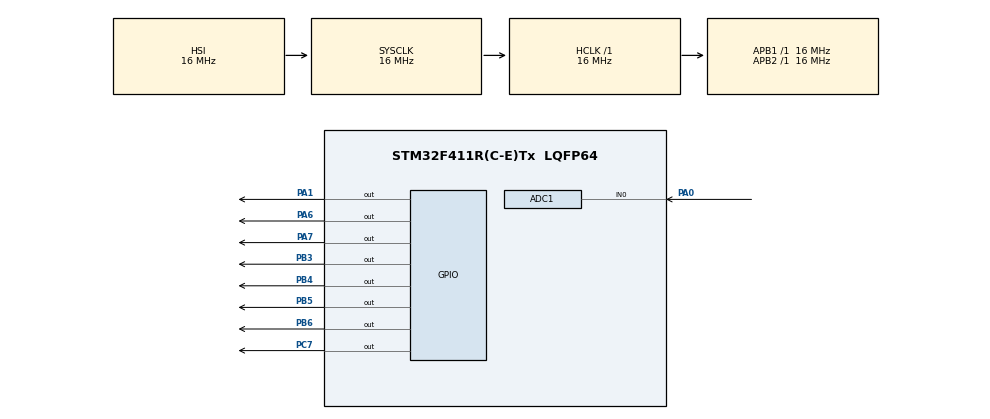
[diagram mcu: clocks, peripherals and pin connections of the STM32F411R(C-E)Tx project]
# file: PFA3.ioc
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ADC1.Channel-2\#ChannelRegularConversion=ADC_CHANNEL_0
ADC1.ClockPrescaler=ADC_CLOCK_SYNC_PCLK_DIV4
ADC1.NbrOfConversionFlag=1
ADC1.Rank-2\#ChannelRegularConversion=1
ADC1.SamplingTime-2\#ChannelRegularConversion=ADC_SAMPLETIME_3CYCLES
ADC1.master=1
Mcu.Family=STM32F4
Mcu.Name=STM32F411R(C-E)Tx
Mcu.Package=LQFP64
NVIC.PriorityGroup=NVIC_PRIORITYGROUP_4
PA0-WKUP.Signal=ADCx_IN0
PA1.Signal=GPIO_Output
PA6.Signal=GPIO_Output
PA7.Signal=GPIO_Output
PB3.Signal=GPIO_Output
PB4.Signal=GPIO_Output
PB5.Signal=GPIO_Output
PB6.Signal=GPIO_Output
PC7.Signal=GPIO_Output
ProjectManager.HeapSize=0x200
ProjectManager.StackSize=0x400
ProjectManager.TargetToolchain=STM32CubeIDE
RCC.AHBFreq_Value=16000000
RCC.APB1Freq_Value=16000000
RCC.APB2Freq_Value=16000000
RCC.CortexFreq_Value=16000000
RCC.HSE_VALUE=25000000
RCC.HSI_VALUE=16000000
RCC.LSE_VALUE=32768
RCC.SYSCLKFreq_VALUE=16000000
RCC.VCOOutputFreq_Value=192000000
SH.ADCx_IN0.0=ADC1_IN0,IN0
VP_TIM10_VS_ClockSourceINT.Mode=Enable_Timer
board=custom

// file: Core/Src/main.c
/* USER CODE BEGIN Header */
/** the temp tensor
  ******************************************************************************
  * @file           : main.c
  * @brief          : Main program body
  ******************************************************************************
  * @attention
  *
  * Copyright (c) 2025 STMicroelectronics.
  * All rights reserved.
  *
  * This software is licensed under terms that can be found in the LICENSE file
  * in the root directory of this software component.
  * If no LICENSE file comes with this software, it is provided AS-IS.
  *
  ******************************************************************************
  */
/* USER CODE END Header */
#include "main.h"

/* USER CODE BEGIN Includes */
#include "DHT22.h"
#include "lcd.h"
#include "MQ135.h"
#include "stdio.h"
/* USER CODE END Includes */

ADC_HandleTypeDef hadc1;

TIM_HandleTypeDef htim10;

void SystemClock_Config(void);
static void MX_GPIO_Init(void);
static void MX_TIM10_Init(void);
static void MX_ADC1_Init(void);

/* USER CODE BEGIN 0 */
float Tempurature = 0 , Humidity = 0 ;
uint8_t status = 0 ;
float ppm;
/* USER CODE END 0 */

int main(void)
{

  /* MCU Configuration--------------------------------------------------------*/

  /* Reset of all peripherals, Initializes the Flash interface and the Systick. */
  HAL_Init();

  /* Configure the system clock */
  SystemClock_Config();

  /* Initialize all configured peripherals */
  MX_GPIO_Init();
  MX_TIM10_Init();
  MX_ADC1_Init();
  MQ135_Init(&hadc1);
  /* USER CODE BEGIN 2 */
  HAL_TIM_Base_Start(&htim10);
  /* USER CODE END 2 */
  // Lcd_PortType ports[] = { D4_GPIO_Port, D5_GPIO_Port, D6_GPIO_Port, D7_GPIO_Port };
        Lcd_PortType ports[] = { GPIOC, GPIOB, GPIOA, GPIOA };
        // Lcd_PinType pins[] = {D4_Pin, D5_Pin, D6_Pin, D7_Pin};
        Lcd_PinType pins[] = {GPIO_PIN_7, GPIO_PIN_6, GPIO_PIN_7, GPIO_PIN_6};
        Lcd_HandleTypeDef lcd;
        // Lcd_create(ports, pins, RS_GPIO_Port, RS_Pin, EN_GPIO_Port, EN_Pin, LCD_4_BIT_MODE);
        lcd = Lcd_create(ports, pins, GPIOB, GPIO_PIN_5, GPIOB, GPIO_PIN_4, LCD_4_BIT_MODE);
        // Calibrate ADC

            HAL_Delay(1000);
            Lcd_clear(&lcd);
            Lcd_string(&lcd, "Test Ready");
            HAL_Delay(3000);
  /* Infinite loop */
  while (1)
  {
	  char buffer[16];
	  	  uint8_t retries = 3;
	  	      while (retries-- > 0)
	  	      {

	  	    	  status = DHT22_Get_Reading(&Tempurature, &Humidity);
	  	          if (status == 1) break;
	  	          HAL_Delay(100);
	  	      }
	  	      ppm = MQ135_ReadPPM();
	  	    if (ppm > 265) {
	  	        HAL_GPIO_WritePin(GPIOB, GPIO_PIN_3, GPIO_PIN_SET);  // Buzzer ON
	  	    } else {
	  	        HAL_GPIO_WritePin(GPIOB, GPIO_PIN_3, GPIO_PIN_RESET); // Buzzer OFF
	  	    }
	  	      if (status == 1)
	  	      {
	  	    	  Lcd_clear(&lcd); // Clear the screen before displaying new values

	  	    	  	      snprintf(buffer, sizeof(buffer), "Tp:%.1fC,", Tempurature);
	  	    	  	      Lcd_cursor(&lcd, 0, 0); // Line 1, position 0
	  	    	  	      Lcd_string(&lcd, buffer);

	  	    	  	      snprintf(buffer, sizeof(buffer), "H:%.1f%%", Humidity);
	  	    	  	      Lcd_cursor(&lcd, 0, 9); // Line 1, position 9
	  	    	  	      Lcd_string(&lcd, buffer);

	  	    	  	      snprintf(buffer, sizeof(buffer), "CO2:%.0fppm", ppm);
	  	    	  	      Lcd_cursor(&lcd, 1, 0); // Ligne 2, position 0
	  	    	  	      Lcd_string(&lcd, buffer);

	  	      }
	  	      else
	  	      {

	  		      Lcd_clear(&lcd);
	  		      Lcd_cursor(&lcd, 0, 0);
	  		      Lcd_string(&lcd, "Sensor Error");
	  	      }
	  	      HAL_Delay(2500);
	  	  /*status = DHT22_Get_Reading(&Tempurature, &Humidity);

	  	  if (status == 1) // Assuming 1 = OK, check based on your DHT22 library
	  	  {
	  	      Lcd_clear(&lcd); // Clear the screen before displaying new values

	  	      snprintf(buffer, sizeof(buffer), "Temp: %.1fC", Tempurature);
	  	      Lcd_cursor(&lcd, 0, 0); // Line 1, position 0
	  	      Lcd_string(&lcd, buffer);

	  	      snprintf(buffer, sizeof(buffer), "Humi: %.1f%%", Humidity);
	  	      Lcd_cursor(&lcd, 1, 0); // Line 2, position 0
	  	      Lcd_string(&lcd, buffer);
	  	  }
	  	  else
	  	  {
	  	      Lcd_clear(&lcd);
	  	      Lcd_cursor(&lcd, 0, 0);
	  	      Lcd_string(&lcd, "Sensor Error");
	  	  }

	  	  HAL_Delay(2500);*/
  }
}

void SystemClock_Config(void)
{
  RCC_OscInitTypeDef RCC_OscInitStruct = {0};
  RCC_ClkInitTypeDef RCC_ClkInitStruct = {0};

  /** Configure the main internal regulator output voltage
  */
  __HAL_RCC_PWR_CLK_ENABLE();
  __HAL_PWR_VOLTAGESCALING_CONFIG(PWR_REGULATOR_VOLTAGE_SCALE1);

  /** Initializes the RCC Oscillators according to the specified parameters
  * in the RCC_OscInitTypeDef structure.
  */
  RCC_OscInitStruct.OscillatorType = RCC_OSCILLATORTYPE_HSI;
  RCC_OscInitStruct.HSIState = RCC_HSI_ON;
  RCC_OscInitStruct.HSICalibrationValue = RCC_HSICALIBRATION_DEFAULT;
  RCC_OscInitStruct.PLL.PLLState = RCC_PLL_NONE;
  if (HAL_RCC_OscConfig(&RCC_OscInitStruct) != HAL_OK)
  {
    Error_Handler();
  }

  /** Initializes the CPU, AHB and APB buses clocks
  */
  RCC_ClkInitStruct.ClockType = RCC_CLOCKTYPE_HCLK|RCC_CLOCKTYPE_SYSCLK
                              |RCC_CLOCKTYPE_PCLK1|RCC_CLOCKTYPE_PCLK2;
  RCC_ClkInitStruct.SYSCLKSource = RCC_SYSCLKSOURCE_HSI;
  RCC_ClkInitStruct.AHBCLKDivider = RCC_SYSCLK_DIV1;
  RCC_ClkInitStruct.APB1CLKDivider = RCC_HCLK_DIV1;
  RCC_ClkInitStruct.APB2CLKDivider = RCC_HCLK_DIV1;

  if (HAL_RCC_ClockConfig(&RCC_ClkInitStruct, FLASH_LATENCY_0) != HAL_OK)
  {
    Error_Handler();
  }
}

static void MX_ADC1_Init(void)
{

  ADC_ChannelConfTypeDef sConfig = {0};

  /** Configure the global features of the ADC (Clock, Resolution, Data Alignment and number of conversion)
  */
  hadc1.Instance = ADC1;
  hadc1.Init.ClockPrescaler = ADC_CLOCK_SYNC_PCLK_DIV4;
  hadc1.Init.Resolution = ADC_RESOLUTION_12B;
  hadc1.Init.ScanConvMode = DISABLE;
  hadc1.Init.ContinuousConvMode = DISABLE;
  hadc1.Init.DiscontinuousConvMode = DISABLE;
  hadc1.Init.ExternalTrigConvEdge = ADC_EXTERNALTRIGCONVEDGE_NONE;
  hadc1.Init.ExternalTrigConv = ADC_SOFTWARE_START;
  hadc1.Init.DataAlign = ADC_DATAALIGN_RIGHT;
  hadc1.Init.NbrOfConversion = 1;
  hadc1.Init.DMAContinuousRequests = DISABLE;
  hadc1.Init.EOCSelection = ADC_EOC_SINGLE_CONV;
  if (HAL_ADC_Init(&hadc1) != HAL_OK)
  {
    Error_Handler();
  }

  /** Configure for the selected ADC regular channel its corresponding rank in the sequencer and its sample time.
  */
  sConfig.Channel = ADC_CHANNEL_0;
  sConfig.Rank = 1;
  sConfig.SamplingTime = ADC_SAMPLETIME_3CYCLES;
  if (HAL_ADC_ConfigChannel(&hadc1, &sConfig) != HAL_OK)
  {
    Error_Handler();
  }

}

static void MX_TIM10_Init(void)
{

  htim10.Instance = TIM10;
  htim10.Init.Prescaler = (SystemCoreClock / 1000000) - 1;  // Pour 1µs
  htim10.Init.CounterMode = TIM_COUNTERMODE_UP;
  htim10.Init.Period = 65535;
  htim10.Init.ClockDivision = TIM_CLOCKDIVISION_DIV1;
  htim10.Init.AutoReloadPreload = TIM_AUTORELOAD_PRELOAD_DISABLE;
  if (HAL_TIM_Base_Init(&htim10) != HAL_OK)
  {
    Error_Handler();
  }

}

static void MX_GPIO_Init(void)
{
  GPIO_InitTypeDef GPIO_InitStruct = {0};

  /* GPIO Ports Clock Enable */
  __HAL_RCC_GPIOA_CLK_ENABLE();
  __HAL_RCC_GPIOC_CLK_ENABLE();
  __HAL_RCC_GPIOB_CLK_ENABLE();

  /*Configure GPIO pin Output Level */
  HAL_GPIO_WritePin(GPIOA, GPIO_PIN_1|GPIO_PIN_6|GPIO_PIN_7, GPIO_PIN_RESET);

  /*Configure GPIO pin Output Level */
  HAL_GPIO_WritePin(GPIOC, GPIO_PIN_7, GPIO_PIN_RESET);

  /*Configure GPIO pin Output Level */
  HAL_GPIO_WritePin(GPIOB, GPIO_PIN_3|GPIO_PIN_4|GPIO_PIN_5|GPIO_PIN_6, GPIO_PIN_RESET);

  /*Configure GPIO pins : PA1 PA6 PA7 */
  GPIO_InitStruct.Pin = GPIO_PIN_1|GPIO_PIN_6|GPIO_PIN_7;
  GPIO_InitStruct.Mode = GPIO_MODE_OUTPUT_PP;
  GPIO_InitStruct.Pull = GPIO_NOPULL;
  GPIO_InitStruct.Speed = GPIO_SPEED_FREQ_LOW;
  HAL_GPIO_Init(GPIOA, &GPIO_InitStruct);

  /*Configure GPIO pin : PC7 */
  GPIO_InitStruct.Pin = GPIO_PIN_7;
  GPIO_InitStruct.Mode = GPIO_MODE_OUTPUT_PP;
  GPIO_InitStruct.Pull = GPIO_NOPULL;
  GPIO_InitStruct.Speed = GPIO_SPEED_FREQ_LOW;
  HAL_GPIO_Init(GPIOC, &GPIO_InitStruct);

  /*Configure GPIO pins : PB3 PB4 PB5 PB6 */
  GPIO_InitStruct.Pin = GPIO_PIN_3|GPIO_PIN_4|GPIO_PIN_5|GPIO_PIN_6;
  GPIO_InitStruct.Mode = GPIO_MODE_OUTPUT_PP;
  GPIO_InitStruct.Pull = GPIO_NOPULL;
  GPIO_InitStruct.Speed = GPIO_SPEED_FREQ_LOW;
  HAL_GPIO_Init(GPIOB, &GPIO_InitStruct);

}

void Error_Handler(void)
{
  __disable_irq();
  while (1)
  {
  }
}
